# GD32H71x_72x register map
File version: 1.0
CPU: CM7 r1p2, little endian, MPU, FPU, 4 interrupt priority bits
Registers are 32-bit, read-write, reset 0x0 unless marked. A register's access mark holds for its fields unless they carry their own. Offsets are from the block's base; [hi:lo] are bit positions.

## TIMER15 — General-level4-timers
Base 0x40014400
Same registers: TIMER16 0x40014800
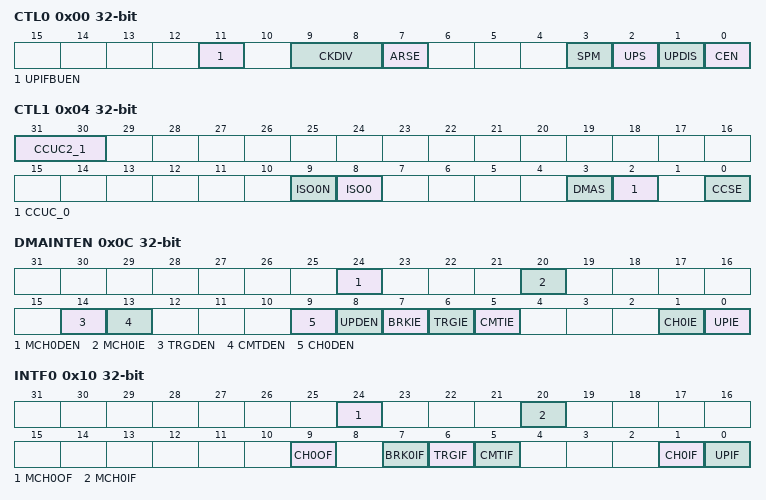
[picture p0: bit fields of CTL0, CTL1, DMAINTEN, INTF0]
0x00 CTL0 — Control register 0
  [11] UPIFBUEN — UPIF bit backup enable
  [9:8] CKDIV — Clock division
  [7] ARSE — Auto-reload shadow enable
  [3] SPM — Single pulse mode
  [2] UPS — Update source
  [1] UPDIS — Update disable
  [0] CEN — Counter enable
0x04 CTL1 — Control register 1
  [31:30] CCUC2_1 — Commutation control shadow register update control
  [9] ISO0N — Idle state of multi mode channel 0 complementary output
  [8] ISO0 — Idle state of channel 0 output
  [3] DMAS — DMA request source selection
  [2] CCUC_0 — Commutation control shadow register update control
  [0] CCSE — Commutation control shadow enable
0x0C DMAINTEN — DMA and interrupt enable register
  [24] MCH0DEN — Multi mode channel 0 capture/compare DMA request enable
  [20] MCH0IE — Multi mode channel 0 capture/compare interrupt enable
  [14] TRGDEN — Trigger DMA request enable
  [13] CMTDEN — Commutation DMA request enable
  [9] CH0DEN — Channel 0 capture/compare DMA request enable
  [8] UPDEN — Update DMA request enable
  [7] BRKIE — Break interrupt enable
  [6] TRGIE — Trigger interrupt enable
  [5] CMTIE — Commutation interrupt enable
  [1] CH0IE — Channel 0 capture/compare interrupt enable
  [0] UPIE — Update interrupt enable
0x10 INTF0 — Interrupt flag register 0
  [24] MCH0OF — Multi mode channel 0 over capture flag
  [20] MCH0IF — Multi mode channel 0 capture/compare interrupt flag
  [9] CH0OF — Channel 0 over capture flag
  [7] BRK0IF — BREAK0 interrupt flag
  [6] TRGIF — Trigger interrupt flag
  [5] CMTIF — Channel commutation interrupt flag
  [1] CH0IF — Channel 0 capture/compare interrupt flag
  [0] UPIF — Update interrupt flag
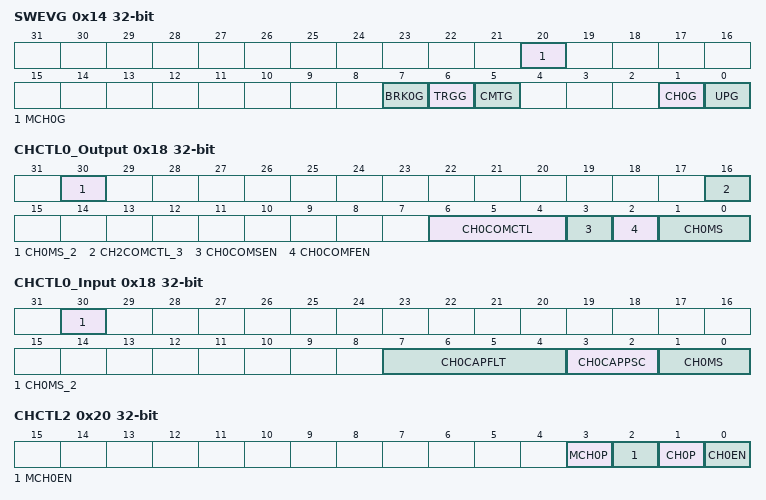
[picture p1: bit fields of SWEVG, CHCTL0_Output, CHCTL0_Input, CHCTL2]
0x14 SWEVG wo — Software event generation register
  [20] MCH0G — Multi mode channel 0 capture or compare event generation.
  [7] BRK0G — BREAK0 event generation
  [6] TRGG — Trigger event generation
  [5] CMTG — Channel commutation event generation
  [1] CH0G — Channel 0 capture or compare event generation
  [0] UPG — Update event generation
0x18 CHCTL0_Output — Channel control register 0 (output mode)
  [30] CH0MS_2 — Channel 0 I/O mode selection
  [16] CH2COMCTL_3 — Bit 3 of channel 1 compare output control
  [6:4] CH0COMCTL — Channel 0 compare output control
  [3] CH0COMSEN — Channel 0 compare output shadow enable
  [2] CH0COMFEN — Channel 0 output compare fast enable
  [1:0] CH0MS — Channel 0 I/O mode selection
0x18 CHCTL0_Input (alternate view of CHCTL0_Output) — Channel control register 0 (input mode)
  [30] CH0MS_2 — Channel 0 I/O mode selection
  [7:4] CH0CAPFLT — Channel 0 input capture filter control
  [3:2] CH0CAPPSC — Channel 0 input capture prescaler
  [1:0] CH0MS — Channel 0 mode selection
0x20 CHCTL2 — Channel control register 2
  [3] MCH0P — Multi mode channel 0 output polarity
  [2] MCH0EN — Multi mode channel 0 capture/compare enable
  [1] CH0P — Channel 0 capture/compare function polarity
  [0] CH0EN — Channel 0 capture/compare function enable
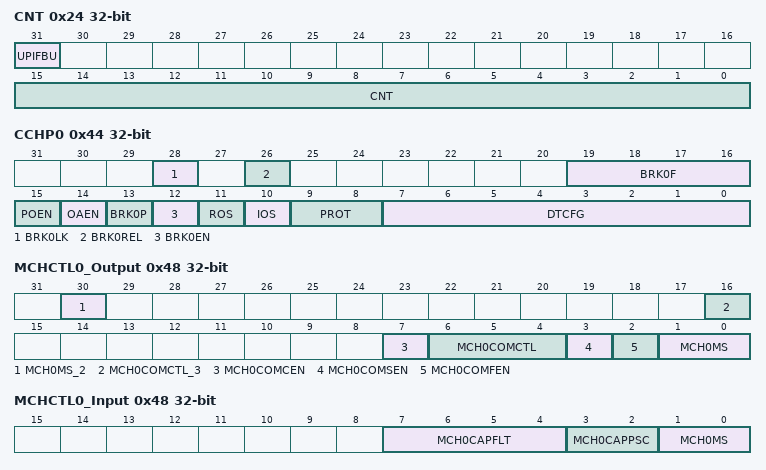
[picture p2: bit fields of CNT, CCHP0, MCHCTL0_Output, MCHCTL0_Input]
0x24 CNT — counter
  [31] UPIFBU — UPIF bit backup
  [15:0] CNT — current counter value
0x28 PSC — prescaler
  [15:0] PSC — Prescaler value of the counter clock
0x2C CAR — Counter auto reload register
  [15:0] CARL — Counter auto reload value
0x30 CREP0 — Counter repetition register
  [7:0] CREP0 — Counter repetition value
0x34 CH0CV — Channel 0 capture/compare value register
  [15:0] CH0VAL — Capture or compare value of channel0
0x44 CCHP0 — Complementary channel protection register 0
  [28] BRK0LK — BREAK0 input locked
  [26] BRK0REL — BREAK0 input released
  [19:16] BRK0F — BREAK0 input signal filter
  [15] POEN — Primary output enable
  [14] OAEN — Output automatic enable
  [13] BRK0P — BREAK0 input signal polarity
  [12] BRK0EN — BREAK0 input signal enable
  [11] ROS — Run mode off-state enable
  [10] IOS — Idle mode off-state enable
  [9:8] PROT — Complementary register protect control
  [7:0] DTCFG — Dead time configuration
0x48 MCHCTL0_Output — Multi mode channel control register 0 (output mode)
  [30] MCH0MS_2 — Multi mode channel 0 I/O mode selection
  [16] MCH0COMCTL_3 — Multi mode channel 0 compare output control.
  [7] MCH0COMCEN — Multi mode channel 0 output compare clear enable
  [6:4] MCH0COMCTL — Multi mode channel 0 output compare control
  [3] MCH0COMSEN — Multi mode channel 0 output compare shadow enable
  [2] MCH0COMFEN — Multi mode channel 0 output compare fast enable
  [1:0] MCH0MS — Multi mode channel 0 I/O mode selection
0x48 MCHCTL0_Input (alternate view of MCHCTL0_Output) — Multi mode channel control register 0 (input mode)
  [7:4] MCH0CAPFLT — Multi mode channel 0 input capture filter control
  [3:2] MCH0CAPPSC — Multi mode channel 0 input capture prescaler
  [1:0] MCH0MS — Multi mode channel 0 I/O mode selection
0x50 MCHFCTL2 — Multi mode channel control register 2
  [1:0] MCH0FP — Multi mode channel 0 capture/compare free polarity
0x54 MCH0CV — Multi mode channel 0 capture/compare value register
  [15:0] MCH0VAL — Capture/compare value of multi mode channel 0
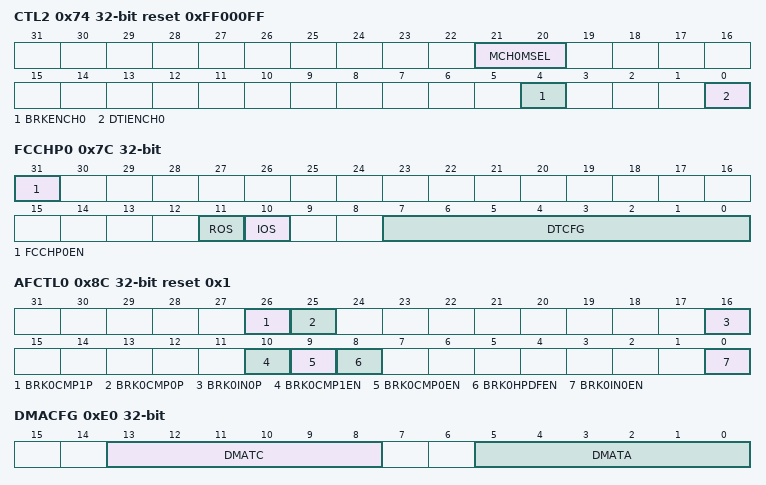
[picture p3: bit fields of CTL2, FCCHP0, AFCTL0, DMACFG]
0x74 CTL2 reset 0xFF000FF — Control register 2
  [21:20] MCH0MSEL — Multi mode channel 0 mode select
  [4] BRKENCH0 — Break control enable for channel 0
  [0] DTIENCH0 — Dead time inserted enable for channel 0
0x7C FCCHP0 — Free complementary channel protection register 0
  [31] FCCHP0EN — Free complementary channel protection register 0 enable
  [11] ROS — Run mode off-state configure
  [10] IOS — Idle mode off-state configure
  [7:0] DTCFG — Dead time configure
0x8C AFCTL0 reset 0x1 — alternate function control register 0
  [26] BRK0CMP1P — BRK CMP1 input polarity
  [25] BRK0CMP0P — BRK CMP0 input polarity
  [16] BRK0IN0P — BREAK0 BRKIN0 alternate function input polarity
  [10] BRK0CMP1EN — BRK CMP1 enable
  [9] BRK0CMP0EN — BRK CMP0 enable
  [8] BRK0HPDFEN — BRK HPDF input enable
  [0] BRK0IN0EN — BREAK0 BRKIN0 alternate function input enable
0x94 WDGPER — Watchdog counter register
  [31:0] WDGPER — Watchdog timeout count
0x98 CREP1 — Counter repetition register 1
  [31:0] CREP1 — Counter repetition value 1
0xE0 DMACFG — DMA configuration register
  [13:8] DMATC — DMA transfer count
  [5:0] DMATA — DMA transfer access start address
0xE4 DMATB — DMA transfer buffer register
  [31:0] DMATB — DMA transfer buffer
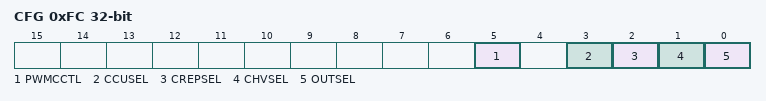
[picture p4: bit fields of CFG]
0xFC CFG — Configuration register
  [5] PWMCCTL — PWM mode change control
  [3] CCUSEL — Commutation control shadow register update select
  [2] CREPSEL — The counter repetition register select
  [1] CHVSEL — Write CHxVAL register selection bit
  [0] OUTSEL — The output value selection bit
